# 3067M register map
File version: 1.0
Registers are 32-bit, access per field, reset 0x0 unless marked. A register's access mark holds for its fields unless they carry their own. Offsets are from the block's base; [hi:lo] are bit positions; 'fields as' and 'values as' point back to an identical list.

## CFD — CFD peripheral interface
Base 0x10020000
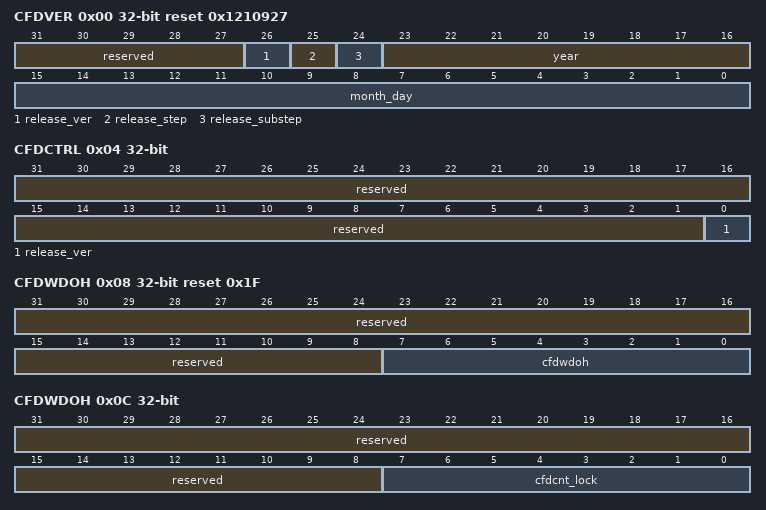
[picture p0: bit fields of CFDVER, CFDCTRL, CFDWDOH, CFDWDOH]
0x00 CFDVER ro reset 0x1210927 — CFD版本信息寄存器
  [31:27] reserved — 保留。
  [26] release_ver — 版本信息。
  [25] release_step — 版本信息。
  [24] release_substep — 版本信息。
  [23:16] year — 年。
  [15:0] month_day — 月日。
0x04 CFDCTRL — CFD控制寄存器。
  [31:1] reserved ro — 保留。
  [0] release_ver rw — CFD使能。 0：不使能； 1：使能。
0x08 CFDWDOH reset 0x1F — CFD检查窗口上限寄存器。
  [31:8] reserved ro — 保留。
  [7:0] cfdwdoh rw — CFD检查窗口上界限，默认为32（从0x0计数到0x1F）个LOSC周期，即检测时间1ms，CFDCNTLOCK大于等于该值说明检测到PLL参考时钟失效（Clock_fail）。
0x0C CFDWDOH ro — CFD计数锁存值寄存器。
  [31:8] reserved — 保留。
  [7:0] cfdcnt_lock — CFD内部计数器计数锁存值。
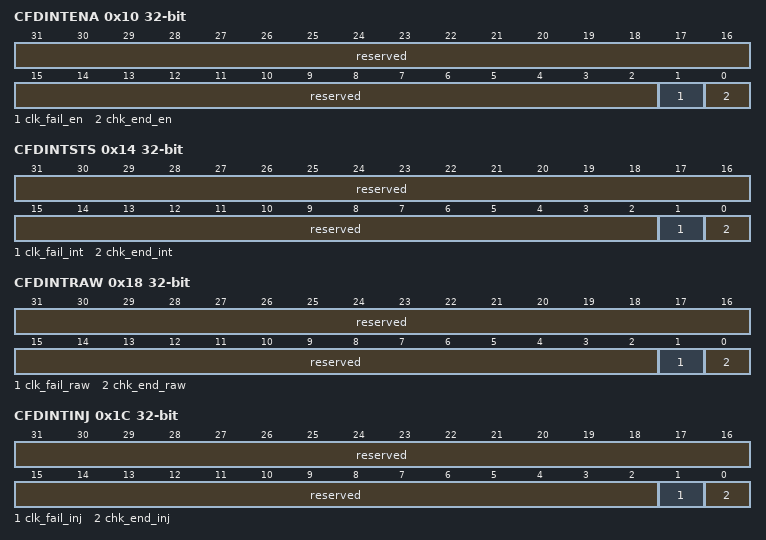
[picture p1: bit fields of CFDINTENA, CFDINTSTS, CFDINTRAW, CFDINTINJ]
0x10 CFDINTENA — CFD中断使能寄存器。
  [31:2] reserved ro — 保留。
  [1] clk_fail_en rw — CFD检测到PLL参考时钟失效中断使能。不使能时，即屏蔽相应的中断状态，不影响相应的原始中断。若全部不使能，CFD不会上报中断给CPU。 0：不使能； 1：使能。
  [0] chk_end_en rw — CFD检测结束中断使能。 0：不使能； 1：使能。
0x14 CFDINTSTS ro — CFD中断状态寄存器。
  [31:2] reserved — 保留。
  [1] clk_fail_int — CFD检测到PLL参考时钟失效中断。 0：无中断； 1：有中断。
  [0] chk_end_int — CFD检测结束中断。 0：无中断； 1：有中断。
0x18 CFDINTRAW RW1C — CFD原始中断寄存器。
  [31:2] reserved — 保留。
  [1] clk_fail_raw — CFD检测到PLL参考时钟失效原始中断。当CFDCTRL[cfden]为1时，才可能产生此中断。 0：无原始中断； 1：有原始中断。写1清除中断。
  [0] chk_end_raw — CFD检测结束中断原始中断。当CFDCTRL[cfden]为1时，才可能产生此中断。 0：无原始中断； 1：有原始中断。写1清除中断。
0x1C CFDINTINJ — CFD中断注入寄存器。
  [31:2] reserved RW1C — 保留。
  [1] clk_fail_inj W1_PULSE — CFD检测到PLL参考时钟失效中断注入。 0：不注入； 1：注入。
  [0] chk_end_inj W1_PULSE — CFD检测结束中断注入。 0：不注入； 1：注入。

## CRC — CRC peripheral interface
Base 0x14800000
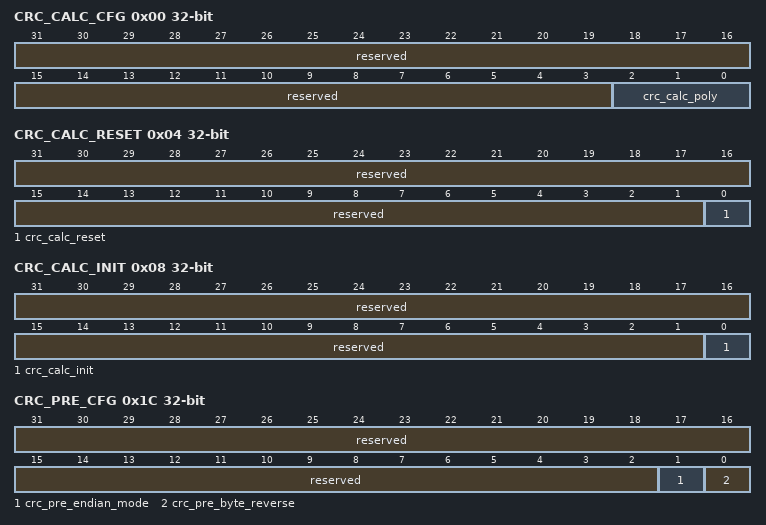
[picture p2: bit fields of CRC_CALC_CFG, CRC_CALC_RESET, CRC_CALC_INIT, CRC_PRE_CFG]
0x00 CRC_CALC_CFG — CRC_CALC_CFG为CRC计算模块，配置寄存器。
  [31:3] reserved ro — 保留。
  [2:0] crc_calc_poly rw — CRC计算模块，多项式配置。 000：CRC-8，多项式0x07； 010：CRC-16，多项式0x8005； 011：CRC-16，多项式0x1021； 100：CRC-32，多项式0x04C11DB7； 其他：保留。
0x04 CRC_CALC_RESET — CRC_CALC_RESET为CRC计算模块，软复位寄存器，其复位CRC计算，不复位配置。
  [31:1] reserved ro — 保留。
  [0] crc_calc_reset rw write-1-clears — CRC计算模块软复，该位域写1自动清零。复位CRC计算，不复位配置。
0x08 CRC_CALC_INIT — CRC_CALC_INIT为CRC计算模块，初始化寄存器。
  [31:1] reserved ro — 保留。
  [0] crc_calc_init rw write-1-clears — CRC初始值加载信号。 该位域写1自动清零，CRC计算初始化。 软件写入该位域，CRC计算初始化完成后，CRC从CRC初始值（CRC_CALC_INIT_VALUE[crc_calc_init_value]位域）开始计算。 注意：软件配置该位域后，再写入CRC_DATA_IN[crc_data_in]位域开始计算。
0x0C CRC_POST_XOR_VALUE rw — CRC_POST_XOR_VALUE为CRC后级处理，异或值寄存器。
  [31:0] crc_post_xor_value — CRC后级处理，异或值（XOR）。
0x10 CRC_CALC_INIT_VALUE rw — CRC_CALC_INIT_VALUE为CRC计算模块，初始值寄存器。
  [31:0] crc_calc_init_value — CRC计算模块，初始值。
0x14 CRC_DATA_IN rw — CRC_DATA_IN为CRC输入数据寄存器。
  [31:0] crc_data_in — CRC输入数据。软件写入需要计算的数据。
0x18 CRC_OUT ro — CRC_OUT为CRC结果寄存器。
  [31:0] crc_out — CRC结果，超过CRC多项式宽度的比特位是0。
0x1C CRC_PRE_CFG — CRC_PRE_CFG为CRC前级处理，配置寄存器。
  [31:2] reserved ro — 保留。
  [1] crc_pre_endian_mode rw — crc_data_in数据大小端。 0：小端； 1：大端。
  [0] crc_pre_byte_reverse rw — crc_data_in数据在字节内，按位反序（RefIn）。 0：不反序； 1：反序。
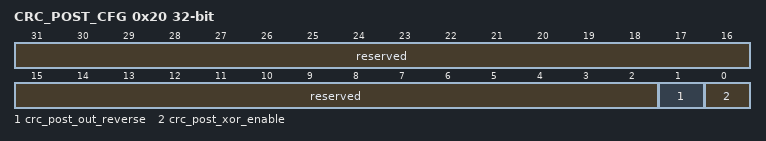
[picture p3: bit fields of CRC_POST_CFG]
0x20 CRC_POST_CFG — CRC_POST_CFG为CRC输出控制寄存器。
  [31:2] reserved ro — 保留。
  [1] crc_post_out_reverse rw — CRC结果在多项式宽度内，按位反序（RefOut）。 0：不反序； 1：反序。
  [0] crc_post_xor_enable rw — CRC结果异或（XOR)。 0：不异或； 1：异或。

## CMM0 — CMM0 peripheral interface
Base 0x10010000
Same registers: CMM1 0x10011000
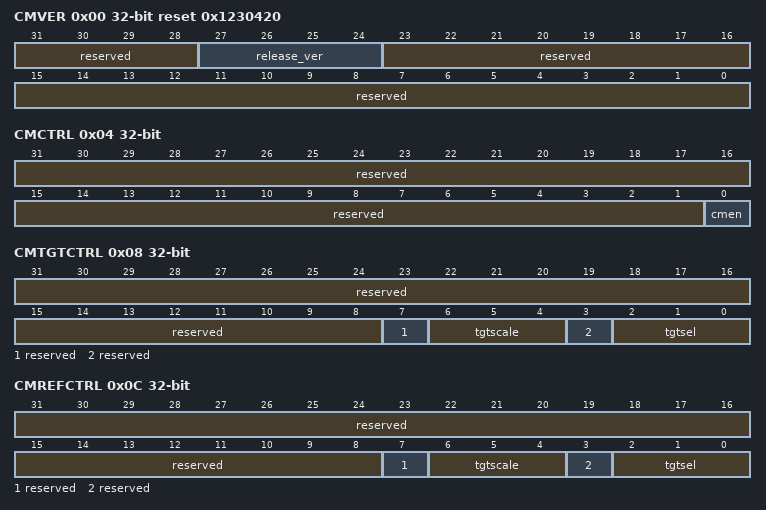
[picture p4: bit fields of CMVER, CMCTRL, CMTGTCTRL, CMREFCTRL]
0x00 CMVER ro reset 0x1230420 — CMM版本信息寄存器。
  [31:28] reserved — 保留。
  [27:24] release_ver — 版本信息。
  [23:0] reserved — 保留。
0x04 CMCTRL — CMM控制寄存器。
  [31:1] reserved ro — 保留。
  [0] cmen rw — CMM使能。 0：不使能； 1：使能。
0x08 CMTGTCTRL — CMM目标时钟控制寄存器。
  [31:8] reserved ro — 保留。
  [7] reserved ro — 保留。
  [6:4] tgtscale rw — CMM目标时钟分频系数，偶数倍占空比50%分频，CMM使用分频后的时钟作为被监控对象。 000：不分频； 001：32分频； 010：128分频； 011：1024分频； 100：8192分频； 其他：8192分频。
  [3] reserved ro — 保留。
  [2:0] tgtsel rw — CMM目标时钟源选择。
0x0C CMREFCTRL — CMM参考时钟控制寄存器。
  fields as CMTGTCTRL
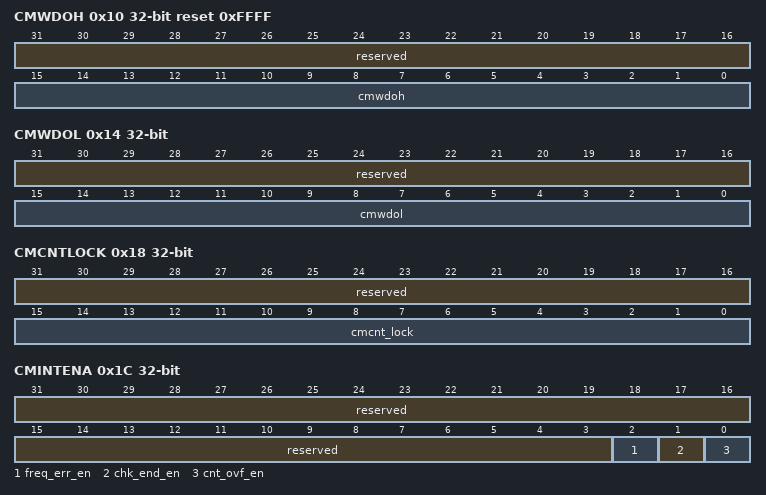
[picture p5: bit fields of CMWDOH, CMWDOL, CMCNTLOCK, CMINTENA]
0x10 CMWDOH reset 0xFFFF — CMM参考时钟控制寄存器。
  [31:16] reserved ro — 保留。
  [15:0] cmwdoh rw — CMM检查窗口上界限，CMCNT大于该值说明频率错误。
0x14 CMWDOL — CMM检查窗口下限寄存器。
  [31:16] reserved ro — 保留。
  [15:0] cmwdol rw — CMM检查窗口下界限，CMCNT小于该值说明频率错误。
0x18 CMCNTLOCK ro — CMM计数锁存值寄存器。
  [31:16] reserved — 保留。
  [15:0] cmcnt_lock — CMM内部计数器计数锁存值。
0x1C CMINTENA — CMM中断使能寄存器。
  [31:3] reserved ro — 保留。
  [2] freq_err_en rw — CMM频率错误中断使能。不使能时，即屏蔽相应的中断状态，不影响相应的原始中断。若全部不使能，CMM不会上报中断给CPU。 0：不使能； 1：使能。
  [1] chk_end_en rw — CMM检测结束中断使能。不使能时，即屏蔽相应的中断状态，不影响相应的原始中断。若全部不使能，CMM不会上报中断给CPU。 0：不使能； 1：使能。
  [0] cnt_ovf_en rw — CMM计数溢出中断使能。不使能时，即屏蔽相应的中断状态，不影响相应的原始中断。若全部不使能，CMM不会上报中断给CPU。 0：不使能； 1：使能。
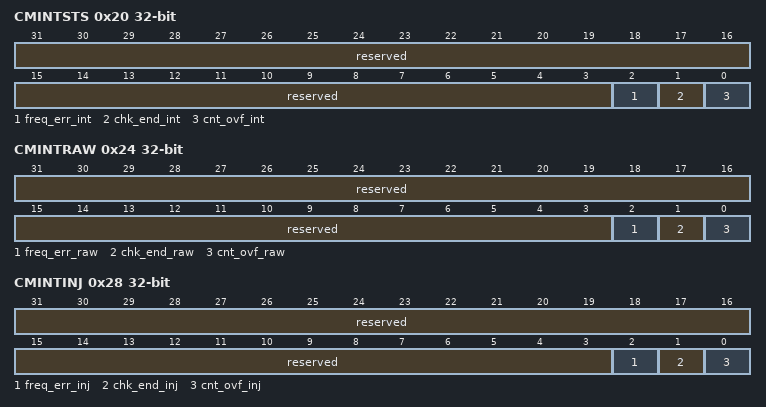
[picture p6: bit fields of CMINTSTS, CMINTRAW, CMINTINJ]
0x20 CMINTSTS ro — CMM中断状态寄存器。
  [31:3] reserved — 保留。
  [2] freq_err_int — CMM频率错误中断状态。 0：无中断； 1：有中断。
  [1] chk_end_int — CMM检测结束中断状态。 0：无中断； 1：有中断。
  [0] cnt_ovf_int — CMM计数溢出中断状态。 0：无中断； 1：有中断。
0x24 CMINTRAW — CMM原始中断寄存器。
  [31:3] reserved ro — 保留。
  [2] freq_err_raw RW1C — CMM频率错误原始中断。当CMCTRL[cmen]为1时，才可能产生此中断。 0：无原始中断； 1：有原始中断。写1清除中断。
  [1] chk_end_raw RW1C — CMM检测结束中断原始中断。当CMCTRL[cmen]为1时，才可能产生此中断。 0：无原始中断； 1：有原始中断。写1清除中断。
  [0] cnt_ovf_raw RW1C — CMM 计数溢出中断原始中断。当CMCTRL[cmen]为1时，才可能产生此中断。 0：无原始中断； 1：有原始中断。写1清除中断。
0x28 CMINTINJ — CMM中断注入寄存器。
  [31:3] reserved ro — 保留。
  [2] freq_err_inj W1_PULSE — CMM频率错误中断注入。 0：不注入； 1：注入。
  [1] chk_end_inj W1_PULSE — CMM检测结束中断注入。 0：不注入； 1：注入。
  [0] cnt_ovf_inj W1_PULSE — CMM计数溢出中断注入。 0：不注入； 1：注入。
